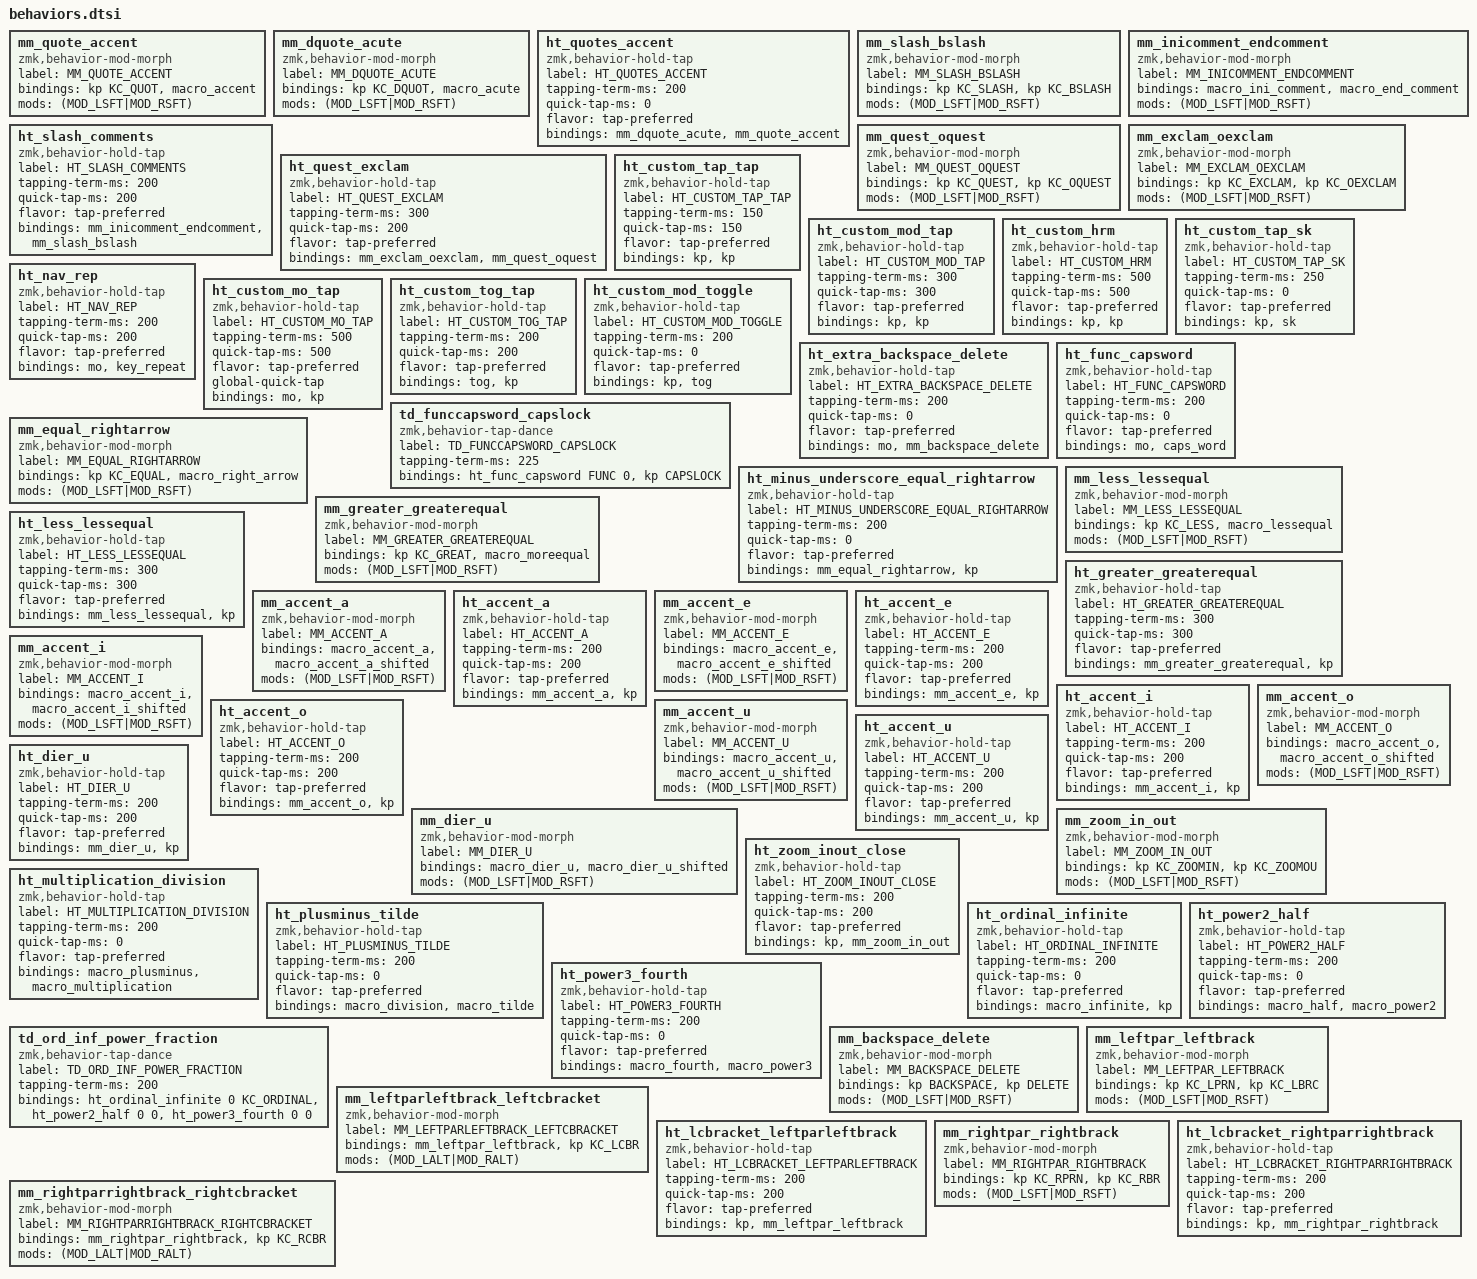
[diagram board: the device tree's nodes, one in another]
#include "keycodes.h"


// LAYER COLEMAK ************************************************************************************************************************
mm_quote_accent: mm_quote_accent {        // ' `
    compatible = "zmk,behavior-mod-morph"; label = "MM_QUOTE_ACCENT";
    #binding-cells = <0>; bindings = <&kp KC_QUOT>, <&macro_accent>;
    mods = <(MOD_LSFT|MOD_RSFT)>;
};
mm_dquote_acute: mm_dquote_acute {        // " ^
    compatible = "zmk,behavior-mod-morph"; label = "MM_DQUOTE_ACUTE";
    #binding-cells = <0>; bindings = <&kp KC_DQUOT>, <&macro_acute>;
    mods = <(MOD_LSFT|MOD_RSFT)>;
};

ht_quotes_accent: ht_quotes_accent {      //  ' ` " ^/ 
compatible = "zmk,behavior-hold-tap"; label = "HT_QUOTES_ACCENT";
    #binding-cells = <2>; tapping-term-ms = <200>; quick-tap-ms = <0>; flavor = "tap-preferred";
    bindings = <&mm_dquote_acute>, <&mm_quote_accent>;
};


mm_slash_bslash: mm_slash_bslash {        
    compatible = "zmk,behavior-mod-morph"; label = "MM_SLASH_BSLASH";
    #binding-cells = <0>; bindings = <&kp KC_SLASH>, <&kp KC_BSLASH>;
    mods = <(MOD_LSFT|MOD_RSFT)>;
};
mm_inicomment_endcomment: mm_inicomment_endcomment {        
    compatible = "zmk,behavior-mod-morph"; label = "MM_INICOMMENT_ENDCOMMENT";
    #binding-cells = <0>; bindings = <&macro_ini_comment>, <&macro_end_comment>;
    mods = <(MOD_LSFT|MOD_RSFT)>;
};

ht_slash_comments: ht_slash_comments {      
compatible = "zmk,behavior-hold-tap"; label = "HT_SLASH_COMMENTS";
    #binding-cells = <2>; tapping-term-ms = <200>; quick-tap-ms = <200>;
    flavor = "tap-preferred";
    bindings = <&mm_inicomment_endcomment>, <&mm_slash_bslash>;
};

mm_quest_oquest: mm_quest_oquest {              //  ? → ¿
    compatible = "zmk,behavior-mod-morph"; label = "MM_QUEST_OQUEST";
    #binding-cells = <0>; bindings = <&kp KC_QUEST>, <&kp KC_OQUEST>;
    mods = <(MOD_LSFT|MOD_RSFT)>;
};
mm_exclam_oexclam: mm_exclam_oexclam {        //   ! → ¡
    compatible = "zmk,behavior-mod-morph"; label = "MM_EXCLAM_OEXCLAM";
    #binding-cells = <0>; bindings = < &kp KC_EXCLAM>, <&kp KC_OEXCLAM>;
    mods = <(MOD_LSFT|MOD_RSFT)>;
};
ht_quest_exclam: ht_quest_exclam {             //  ? ¿ ! ¡
compatible = "zmk,behavior-hold-tap"; label = "HT_QUEST_EXCLAM";
    #binding-cells = <2>; tapping-term-ms = <300>; quick-tap-ms = <200>; flavor = "tap-preferred";
    bindings = <&mm_exclam_oexclam>, <&mm_quest_oquest>;
};

ht_custom_tap_tap: ht_custom_tap_tap {             // REUSABLE tap for both the hold and the tap actions, so two keys are expected as parameters
    compatible = "zmk,behavior-hold-tap"; label = "HT_CUSTOM_TAP_TAP";
    #binding-cells = <2>; tapping-term-ms = <150>; quick-tap-ms = <150>; flavor = "tap-preferred";
    bindings = <&kp>, <&kp>;
};
ht_custom_mod_tap: ht_custom_mod_tap {             // longer quick-tap for the G/V mod taps
    compatible = "zmk,behavior-hold-tap"; label = "HT_CUSTOM_MOD_TAP";
    #binding-cells = <2>; tapping-term-ms = <300>; quick-tap-ms = <300>; flavor = "tap-preferred";
    bindings = <&kp>, <&kp>;
};
ht_custom_hrm: ht_custom_hrm {             // for home row mods with higher tapping-term to avoid misfires, as they aren't used that often so the added delay is not much of an issue
    compatible = "zmk,behavior-hold-tap"; label = "HT_CUSTOM_HRM";
    #binding-cells = <2>; tapping-term-ms = <500>; quick-tap-ms = <500>; flavor = "tap-preferred";
    bindings = <&kp>, <&kp>;
};
//ht_extra_backspace_delete: ht_extra_backspace_delete {             // with massive tapping-term, as it is rarely used
//    compatible = "zmk,behavior-hold-tap"; label = "HT_EXTRA_BACKSPACE_DELETE";
//    #binding-cells = <2>; tapping-term-ms = <500>; quick-tap-ms = <500>; flavor = "tap-preferred";
//    bindings = <&kp>, <&kp>;
//};
ht_custom_tap_sk: ht_custom_tap_sk {             // REUSABLE tap for both the hold and the tap actions, so two keys are expected as parameters
    compatible = "zmk,behavior-hold-tap"; label = "HT_CUSTOM_TAP_SK";
    #binding-cells = <2>; tapping-term-ms = <250>; quick-tap-ms = <0>; flavor = "tap-preferred";
    bindings = <&kp>, <&sk>;
};
ht_nav_rep: ht_nav_rep {             //  NAV - REP
    compatible = "zmk,behavior-hold-tap"; label = "HT_NAV_REP";
    #binding-cells = <2>; tapping-term-ms = <200>; quick-tap-ms = <200>; flavor = "tap-preferred";
    bindings = <&mo>, <&key_repeat>;
};
//ht_npad_rep: ht_npad_rep {             //  NAV - REP
//   compatible = "zmk,behavior-hold-tap"; label = "HT_NPAD_REP";
//    #binding-cells = <2>; tapping-term-ms = <200>; quick-tap-ms = <125>; global-quick-tap; flavor = "tap-preferred";
//    bindings = <&tog>, <&key_repeat>;
//};
//td_nav_rep_npad_togglenpad: td_nav_rep_npad_togglenpad {     // test TAP-DANCE + two LAYER-TAPS      NAV-REP + NPADoREP + TOGGLENPAD
//    compatible = "zmk,behavior-tap-dance"; label = "TD_NAV_REP_NPAD_TOGGLENPAD";
//    #binding-cells = <0>; tapping-term-ms = <250>;
//    bindings = <&ht_nav_rep NAV 0>, <&ht_npad_rep NPAD 0>;
//};
//td_num_spc_npad_togglenpad: td_num_spc_npad_togglenpad {     // test TAP-DANCE + two LAYER-TAPS      NAV-REP + NPADoREP + TOGGLENPAD
//    compatible = "zmk,behavior-tap-dance"; label = "TD_NUM_SPC_NPAD_TOGGLENPAD";
//    #binding-cells = <0>; tapping-term-ms = <250>;
//    bindings = <&ht_custom_mo_tap NUM SPACE>, <&ht_custom_tog_tap NPAD SPACE>, <&kp SPACE>;
//};
ht_custom_mo_tap: ht_custom_mo_tap {             
    compatible = "zmk,behavior-hold-tap"; label = "HT_CUSTOM_MO_TAP";
    #binding-cells = <2>; tapping-term-ms = <500>; quick-tap-ms = <500>; flavor = "tap-preferred"; global-quick-tap; 
    bindings = <&mo>, <&kp>;
};   
ht_custom_tog_tap: ht_custom_tog_tap {             
    compatible = "zmk,behavior-hold-tap"; label = "HT_CUSTOM_TOG_TAP";
    #binding-cells = <2>; tapping-term-ms = <200>; quick-tap-ms = <200>; flavor = "tap-preferred";
    bindings = <&tog>, <&kp>;
};          
ht_custom_mod_toggle: ht_custom_mod_toggle {             // RCTRL → TOGGLE LANGUAGE LAYER
    compatible = "zmk,behavior-hold-tap"; label = "HT_CUSTOM_MOD_TOGGLE";
    #binding-cells = <2>; tapping-term-ms = <200>; quick-tap-ms = <0>; flavor = "tap-preferred";
    bindings = <&kp>, <&tog>;
};  
//td_shift_func_capslock: td_shift_func_capslock {     // test TAP-DANCE + two LAYER-TAPS      NAV-REP + NPADoREP + TOGGLENPAD
//    compatible = "zmk,behavior-tap-dance"; label = "TD_SHIFT_FUNC_CAPSLOCK";
//   #binding-cells = <0>; tapping-term-ms = <250>;
//    bindings = <&ht_custom_tap_sk LSHIFT LSHIFT>, <&kp CAPSLOCK>;
//};        
ht_extra_backspace_delete: ht_extra_backspace_delete {             // RCTRL → TOGGLE LANGUAGE LAYER
    compatible = "zmk,behavior-hold-tap"; label = "HT_EXTRA_BACKSPACE_DELETE";
    #binding-cells = <2>; tapping-term-ms = <200>; quick-tap-ms = <0>; flavor = "tap-preferred";
    bindings = <&mo>, <&mm_backspace_delete>;
};  
//ht_capslock_capsword: ht_capslock_capsword {             // RCTRL → TOGGLE LANGUAGE LAYER
//    compatible = "zmk,behavior-hold-tap"; label = "HT_CAPSLOCK_CAPSWORD";
//    #binding-cells = <2>; tapping-term-ms = <200>; quick-tap-ms = <0>; flavor = "tap-preferred";
//    bindings = <&kp>, <&caps_word>;
//};  
ht_func_capsword: ht_func_capsword {             // RCTRL → TOGGLE LANGUAGE LAYER
    compatible = "zmk,behavior-hold-tap"; label = "HT_FUNC_CAPSWORD";
    #binding-cells = <2>; tapping-term-ms = <200>; quick-tap-ms = <0>; flavor = "tap-preferred";
    bindings = <&mo>, <&caps_word>;
}; 
td_funccapsword_capslock: td_funccapsword_capslock {     // CAPSWORD → CAPSLOCK
    compatible = "zmk,behavior-tap-dance"; label = "TD_FUNCCAPSWORD_CAPSLOCK";
    #binding-cells = <0>; tapping-term-ms = <225>;
    bindings = <&ht_func_capsword FUNC 0>, <&kp CAPSLOCK>;
};
//ht_num_backspace_delete: ht_num_backspace_delete {             // RCTRL → TOGGLE LANGUAGE LAYER
//    compatible = "zmk,behavior-hold-tap"; label = "HT_NUM_BACKSPACE_DELETE";
//    #binding-cells = <2>; tapping-term-ms = <200>; quick-tap-ms = <0>; flavor = "tap-preferred";
//    bindings = <&mo>, <&mm_backspace_delete>;
//};  
mm_equal_rightarrow: mm_equal_rightarrow {                                               //  = → →
    compatible = "zmk,behavior-mod-morph"; label = "MM_EQUAL_RIGHTARROW";
    #binding-cells = <0>; bindings = <&kp KC_EQUAL>, <&macro_right_arrow>;
    mods = <(MOD_LSFT|MOD_RSFT)>;
};
ht_minus_underscore_equal_rightarrow: ht_minus_underscore_equal_rightarrow {             // -_ → =→
    compatible = "zmk,behavior-hold-tap"; label = "HT_MINUS_UNDERSCORE_EQUAL_RIGHTARROW";
    #binding-cells = <2>; tapping-term-ms = <200>; quick-tap-ms = <0>; flavor = "tap-preferred";
    bindings = <&mm_equal_rightarrow>, <&kp>;
};  
 
mm_equal_rightarrow: mm_equal_rightarrow {                                               //  = → →
    compatible = "zmk,behavior-mod-morph"; label = "MM_EQUAL_RIGHTARROW";
    #binding-cells = <0>; bindings = <&kp KC_EQUAL>, <&macro_right_arrow>;
    mods = <(MOD_LSFT|MOD_RSFT)>;
};
mm_less_lessequal: mm_less_lessequal {                                                   //  <≤
    compatible = "zmk,behavior-mod-morph"; label = "MM_LESS_LESSEQUAL";
    #binding-cells = <0>; bindings = <&kp KC_LESS>, <&macro_lessequal>;
    mods = <(MOD_LSFT|MOD_RSFT)>;
};
mm_greater_greaterequal: mm_greater_greaterequal {                                                   //  >≥
    compatible = "zmk,behavior-mod-morph"; label = "MM_GREATER_GREATEREQUAL";
    #binding-cells = <0>; bindings = <&kp KC_GREAT>, <&macro_moreequal>;
    mods = <(MOD_LSFT|MOD_RSFT)>;
};
ht_less_lessequal: ht_less_lessequal {                                                   // < → ≤
    compatible = "zmk,behavior-hold-tap"; label = "HT_LESS_LESSEQUAL";
    #binding-cells = <2>; tapping-term-ms = <300>; quick-tap-ms = <300>; flavor = "tap-preferred";
    bindings = <&mm_less_lessequal>, <&kp>;
};  
ht_greater_greaterequal: ht_greater_greaterequal {                                       // > → ≥
    compatible = "zmk,behavior-hold-tap"; label = "HT_GREATER_GREATEREQUAL";
    #binding-cells = <2>; tapping-term-ms = <300>; quick-tap-ms = <300>; flavor = "tap-preferred";
    bindings = <&mm_greater_greaterequal>, <&kp>;
}; 
// END LAYER COLEMAK ********************************************************************************************************************


// LAYER ACCENTS ************************************************************************************************************************
mm_accent_a: mm_accent_a {              //  á → Á
    compatible = "zmk,behavior-mod-morph"; label = "MM_ACCENT_A";
    #binding-cells = <0>; bindings = <&macro_accent_a>, <&macro_accent_a_shifted>;
    mods = <(MOD_LSFT|MOD_RSFT)>;
};
ht_accent_a: ht_accent_a {             //  aA → áÁ
compatible = "zmk,behavior-hold-tap"; label = "HT_ACCENT_A";
    #binding-cells = <2>; tapping-term-ms = <200>; quick-tap-ms = <200>; flavor = "tap-preferred";
    bindings = <&mm_accent_a>, <&kp>;
};                
    mm_accent_e: mm_accent_e {              //  é → É
    compatible = "zmk,behavior-mod-morph"; label = "MM_ACCENT_E";
    #binding-cells = <0>; bindings = <&macro_accent_e>, <&macro_accent_e_shifted>;
    mods = <(MOD_LSFT|MOD_RSFT)>;
};
ht_accent_e: ht_accent_e {             //  eE → éÉ
    compatible = "zmk,behavior-hold-tap"; label = "HT_ACCENT_E";
    #binding-cells = <2>; tapping-term-ms = <200>; quick-tap-ms = <200>; flavor = "tap-preferred";
    bindings = <&mm_accent_e>, <&kp>;
};    
mm_accent_i: mm_accent_i {              //  í → Í
    compatible = "zmk,behavior-mod-morph"; label = "MM_ACCENT_I";
    #binding-cells = <0>; bindings = <&macro_accent_i>, <&macro_accent_i_shifted>;
    mods = <(MOD_LSFT|MOD_RSFT)>;
};
ht_accent_i: ht_accent_i {             //  iI → íÍ
compatible = "zmk,behavior-hold-tap"; label = "HT_ACCENT_I";
    #binding-cells = <2>; tapping-term-ms = <200>; quick-tap-ms = <200>; flavor = "tap-preferred";
    bindings = <&mm_accent_i>, <&kp>;
};                
mm_accent_o: mm_accent_o {              //  ó → Ó
    compatible = "zmk,behavior-mod-morph"; label = "MM_ACCENT_O";
    #binding-cells = <0>; bindings = <&macro_accent_o>, <&macro_accent_o_shifted>;
    mods = <(MOD_LSFT|MOD_RSFT)>;
};
ht_accent_o: ht_accent_o {             //  oO → óÓ
compatible = "zmk,behavior-hold-tap"; label = "HT_ACCENT_O";
    #binding-cells = <2>; tapping-term-ms = <200>; quick-tap-ms = <200>; flavor = "tap-preferred";
    bindings = <&mm_accent_o>, <&kp>;
};  
mm_accent_u: mm_accent_u {              //  ú → Ú
    compatible = "zmk,behavior-mod-morph"; label = "MM_ACCENT_U";
    #binding-cells = <0>; bindings = <&macro_accent_u>, <&macro_accent_u_shifted>;
    mods = <(MOD_LSFT|MOD_RSFT)>;
};
mm_dier_u: mm_dier_u {              //  ü → Ü
    compatible = "zmk,behavior-mod-morph"; label = "MM_DIER_U";
    #binding-cells = <0>; bindings = <&macro_dier_u>, <&macro_dier_u_shifted>;
    mods = <(MOD_LSFT|MOD_RSFT)>;
};
ht_accent_u: ht_accent_u {             //  uU → úÚ
compatible = "zmk,behavior-hold-tap"; label = "HT_ACCENT_U";
    #binding-cells = <2>; tapping-term-ms = <200>; quick-tap-ms = <200>; flavor = "tap-preferred";
    bindings = <&mm_accent_u>, <&kp>;
};  
//td_accent_dier_u: td_accent_dier_u {     // uU / úÚ → üÜ
//    compatible = "zmk,behavior-tap-dance"; label = "TD_ACCENT_DIER_U";
//    #binding-cells = <0>; tapping-term-ms = <200>;
//    bindings = <&ht_accent_u 0 U>, <&mm_dier_u>;
//};
ht_dier_u: ht_dier_u {             //  uU → úÚ
compatible = "zmk,behavior-hold-tap"; label = "HT_DIER_U";
    #binding-cells = <2>; tapping-term-ms = <200>; quick-tap-ms = <200>; flavor = "tap-preferred";
    bindings = <&mm_dier_u>, <&kp>;
};  
// END LAYER ACCENTS ********************************************************************************************************************


// LAYER NAV ****************************************************************************************************************************
mm_zoom_in_out: mm_zoom_in_out {              //  
    compatible = "zmk,behavior-mod-morph"; label = "MM_ZOOM_IN_OUT";
    #binding-cells = <0>; bindings = <&kp KC_ZOOMIN>, <&kp KC_ZOOMOU>;
    mods = <(MOD_LSFT|MOD_RSFT)>;
};
ht_zoom_inout_close: ht_zoom_inout_close {             //  
    compatible = "zmk,behavior-hold-tap"; label = "HT_ZOOM_INOUT_CLOSE";
    #binding-cells = <2>; tapping-term-ms = <200>; quick-tap-ms = <200>; flavor = "tap-preferred";
    bindings = <&kp>, <&mm_zoom_in_out>;
}; 
// END LAYER NAV ************************************************************************************************************************


// LAYER NUM ****************************************************************************************************************************
ht_multiplication_division: ht_multiplication_division {             // -_ → =→
    compatible = "zmk,behavior-hold-tap"; label = "HT_MULTIPLICATION_DIVISION";
    #binding-cells = <2>; tapping-term-ms = <200>; quick-tap-ms = <0>; flavor = "tap-preferred";
    bindings = <&macro_plusminus>, <&macro_multiplication>;
};              
ht_plusminus_tilde: ht_plusminus_tilde {             // -_ → =→
    compatible = "zmk,behavior-hold-tap"; label = "HT_PLUSMINUS_TILDE";
    #binding-cells = <2>; tapping-term-ms = <200>; quick-tap-ms = <0>; flavor = "tap-preferred";
    bindings = <&macro_division>, <&macro_tilde>;
};  
ht_ordinal_infinite: ht_ordinal_infinite {             // º → ∞
    compatible = "zmk,behavior-hold-tap"; label = "HT_ORDINAL_INFINITE";
    #binding-cells = <2>; tapping-term-ms = <200>; quick-tap-ms = <0>; flavor = "tap-preferred";
    bindings = <&macro_infinite>, <&kp>;
};  
ht_power2_half: ht_power2_half {             // ² → ½
    compatible = "zmk,behavior-hold-tap"; label = "HT_POWER2_HALF";
    #binding-cells = <2>; tapping-term-ms = <200>; quick-tap-ms = <0>; flavor = "tap-preferred";
    bindings = <&macro_half>, <&macro_power2>;
};             
ht_power3_fourth: ht_power3_fourth {             // ³ → ¼
    compatible = "zmk,behavior-hold-tap"; label = "HT_POWER3_FOURTH";
    #binding-cells = <2>; tapping-term-ms = <200>; quick-tap-ms = <0>; flavor = "tap-preferred";
    bindings = <&macro_fourth>, <&macro_power3>;
};  
td_ord_inf_power_fraction: td_ord_inf_power_fraction {     // º ² ³ ∞ ½ ¼
    compatible = "zmk,behavior-tap-dance"; label = "TD_ORD_INF_POWER_FRACTION";
    #binding-cells = <0>; tapping-term-ms = <200>;
    bindings = <&ht_ordinal_infinite 0 KC_ORDINAL>, <&ht_power2_half 0 0>, <&ht_power3_fourth 0 0>;
};
// END LAYER NUM ************************************************************************************************************************



// LAYER NPAD ***************************************************************************************************************************
mm_backspace_delete: mm_backspace_delete {              //  
    compatible = "zmk,behavior-mod-morph"; label = "MM_BACKSPACE_DELETE";
    #binding-cells = <0>; bindings = <&kp BACKSPACE>, <&kp DELETE>;
    mods = <(MOD_LSFT|MOD_RSFT)>;
};
// END LAYER NPAD ***********************************************************************************************************************




// COMBOS *******************************************************************************************************************************
mm_leftpar_leftbrack: mm_leftpar_leftbrack {              //  ( → [
    compatible = "zmk,behavior-mod-morph"; label = "MM_LEFTPAR_LEFTBRACK";
    #binding-cells = <0>; bindings = <&kp KC_LPRN>, <&kp KC_LBRC>;
    mods = <(MOD_LSFT|MOD_RSFT)>;
};
mm_leftparleftbrack_leftcbracket: mm_leftparleftbrack_leftcbracket {              //  [( → {
    compatible = "zmk,behavior-mod-morph"; label = "MM_LEFTPARLEFTBRACK_LEFTCBRACKET";
    #binding-cells = <0>; bindings = <&mm_leftpar_leftbrack>, <&kp KC_LCBR>;
    mods = <(MOD_LALT|MOD_RALT)>;
};    
ht_lcbracket_leftparleftbrack: ht_lcbracket_leftparleftbrack {             //  [( → {
compatible = "zmk,behavior-hold-tap"; label = "HT_LCBRACKET_LEFTPARLEFTBRACK";
    #binding-cells = <2>; tapping-term-ms = <200>; quick-tap-ms = <200>; flavor = "tap-preferred";
    bindings = <&kp>, <&mm_leftpar_leftbrack>;
};    

mm_rightpar_rightbrack: mm_rightpar_rightbrack {              //  ) → ]
    compatible = "zmk,behavior-mod-morph"; label = "MM_RIGHTPAR_RIGHTBRACK";
    #binding-cells = <0>; bindings = <&kp KC_RPRN>, <&kp KC_RBR>;
    mods = <(MOD_LSFT|MOD_RSFT)>;
};
mm_rightparrightbrack_rightcbracket: mm_rightparrightbrack_rightcbracket {              //  )] → }
    compatible = "zmk,behavior-mod-morph"; label = "MM_RIGHTPARRIGHTBRACK_RIGHTCBRACKET";
    #binding-cells = <0>; bindings = <&mm_rightpar_rightbrack>, <&kp KC_RCBR>;
    mods = <(MOD_LALT|MOD_RALT)>;
};    
ht_lcbracket_rightparrightbrack: ht_lcbracket_rightparrightbrack {             //  )] → }
compatible = "zmk,behavior-hold-tap"; label = "HT_LCBRACKET_RIGHTPARRIGHTBRACK";
    #binding-cells = <2>; tapping-term-ms = <200>; quick-tap-ms = <200>; flavor = "tap-preferred";
    bindings = <&kp>, <&mm_rightpar_rightbrack>;
};    
// END COMBOS ****************************************************************************************************************************
